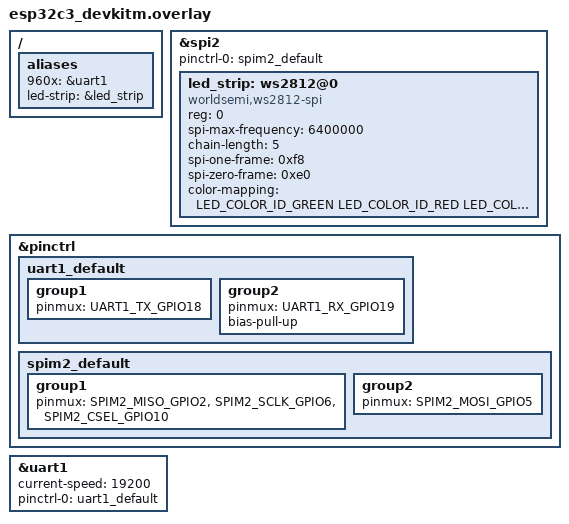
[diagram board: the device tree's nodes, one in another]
#include <zephyr/dt-bindings/led/led.h>

&spi2 {

  status = "okay";
  pinctrl-0 = <&spim2_default>;
	pinctrl-names = "default";


  led_strip: ws2812@0 {
    compatible = "worldsemi,ws2812-spi";

		reg = <0>; /* ignored, but necessary for SPI bindings */
		spi-max-frequency = <6400000>;
    
    /* https://docs.zephyrproject.org/latest/build/dts/api/bindings/led_strip/worldsemi,ws2812-spi.html */
		chain-length = <5>; /* arbitrary; change at will */
		spi-one-frame = <0xf8>; /* 11111100: 625 ns high and 625 ns low */
		spi-zero-frame = <0xe0>; /* 00000011: 312.5 ns high and 937.5 ns low */
		color-mapping = <LED_COLOR_ID_GREEN LED_COLOR_ID_RED LED_COLOR_ID_BLUE>;
	};

};

&pinctrl {

  uart1_default: uart1_default {
		
    group1 {
			pinmux = <UART1_TX_GPIO18>; 
		};

		group2 {
			pinmux = <UART1_RX_GPIO19>;
			bias-pull-up;
		};

	};

	spim2_default: spim2_default {
		group1 {
			pinmux =  <SPIM2_MISO_GPIO2>,
				        <SPIM2_SCLK_GPIO6>,
				        <SPIM2_CSEL_GPIO10>;
		};
		group2 {
			pinmux = <SPIM2_MOSI_GPIO5>;
		};
	};

};

&uart1 {
	status = "okay";
	current-speed = <19200>;
	pinctrl-0 = <&uart1_default>;
	pinctrl-names = "default";
};

/ {

  aliases {
    960x = &uart1;
    led-strip = &led_strip;
  };

};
